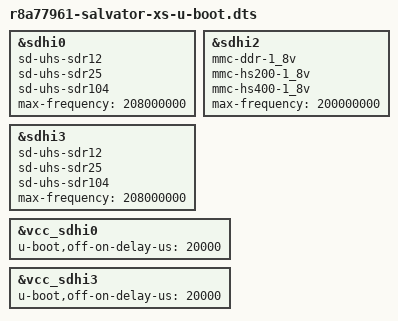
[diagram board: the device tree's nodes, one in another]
// SPDX-License-Identifier: GPL-2.0
/*
 * Device Tree Source extras for U-Boot for the Salvator-X 2nd version board
 *
 * Copyright (C) 2021 Renesas Electronics Corp.
 */

#include "r8a77961-salvator-xs.dts"
#include "r8a77961-u-boot.dtsi"

&sdhi0 {
	sd-uhs-sdr12;
	sd-uhs-sdr25;
	sd-uhs-sdr104;
	max-frequency = <208000000>;
};

&sdhi2 {
	mmc-ddr-1_8v;
	mmc-hs200-1_8v;
	mmc-hs400-1_8v;
	max-frequency = <200000000>;
};

&sdhi3 {
	sd-uhs-sdr12;
	sd-uhs-sdr25;
	sd-uhs-sdr104;
	max-frequency = <208000000>;
};

&vcc_sdhi0 {
	u-boot,off-on-delay-us = <20000>;
};

&vcc_sdhi3 {
	u-boot,off-on-delay-us = <20000>;
};
